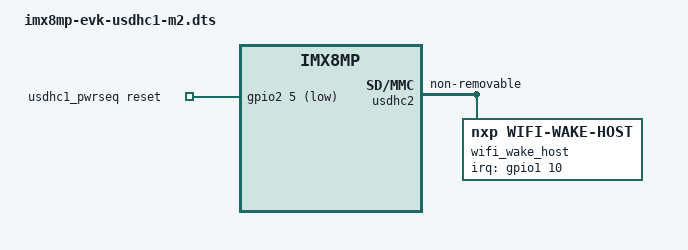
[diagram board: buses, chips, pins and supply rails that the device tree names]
// SPDX-License-Identifier: (GPL-2.0 OR MIT)
/*
 * Copyright 2021 NXP
 */

#include "imx8mp-evk.dts"

/ {
	usdhc1_pwrseq: usdhc1_pwrseq {
		compatible = "mmc-pwrseq-simple";
		reset-gpios = <&gpio2 5 GPIO_ACTIVE_LOW>;
	};
};

&pcie {
	status = "disabled";
	/delete-node/ wifi_wake_host;
};

&pcie_phy {
	status = "disabled";
};

&usdhc2 {
	keep-power-in-suspend;
	non-removable;
	wakeup-source;
	mmc-pwrseq = <&usdhc1_pwrseq>;
	fsl,sdio-async-interrupt-enabled;
	status = "okay";

	wifi_wake_host {
		compatible = "nxp,wifi-wake-host";
		interrupt-parent = <&gpio1>;
		interrupts = <10 IRQ_TYPE_LEVEL_LOW>;
		interrupt-names = "host-wake";
	};
};
